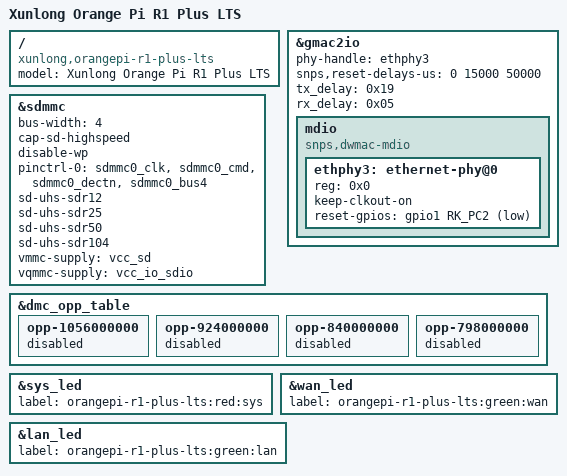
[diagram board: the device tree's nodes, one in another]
// SPDX-License-Identifier: (GPL-2.0+ OR MIT)
#include "rk3328-orangepi-r1-plus.dts"

/ {
	model = "Xunlong Orange Pi R1 Plus LTS";
	compatible = "xunlong,orangepi-r1-plus-lts", "rockchip,rk3328";
};

/delete-node/ &rtl8211e;
&gmac2io {
        phy-handle = <&ethphy3>;
        snps,reset-delays-us = <0 15000 50000>;
        tx_delay = <0x19>;
        rx_delay = <0x05>;
        status = "okay";

        mdio {
                compatible = "snps,dwmac-mdio";
                #address-cells = <1>;
                #size-cells = <0>;

                ethphy3: ethernet-phy@0 {
                        reg = <0x0>;
                        keep-clkout-on;
                       reset-gpios = <&gpio1 RK_PC2 GPIO_ACTIVE_LOW>;
                };
        };
};

&sdmmc {
      bus-width = <4>;
      cap-sd-highspeed;
      disable-wp;
      pinctrl-0 = <&sdmmc0_clk>, <&sdmmc0_cmd>, <&sdmmc0_dectn>, <&sdmmc0_bus4>;
      pinctrl-names = "default";
      sd-uhs-sdr12;
      sd-uhs-sdr25;
      sd-uhs-sdr50;
      sd-uhs-sdr104;
      vmmc-supply = <&vcc_sd>;
      vqmmc-supply = <&vcc_io_sdio>;
      status = "okay";
};

&dmc_opp_table {
        opp-1056000000 {
                status = "disabled";
        };
        opp-924000000 {
                status = "disabled";
        };
        opp-840000000 {
                status = "disabled";
        };
        opp-798000000 {
                status = "disabled";
        };
};

&sys_led {
       label = "orangepi-r1-plus-lts:red:sys";
};

&wan_led {
       label = "orangepi-r1-plus-lts:green:wan";
};

&lan_led {
       label = "orangepi-r1-plus-lts:green:lan";
};
